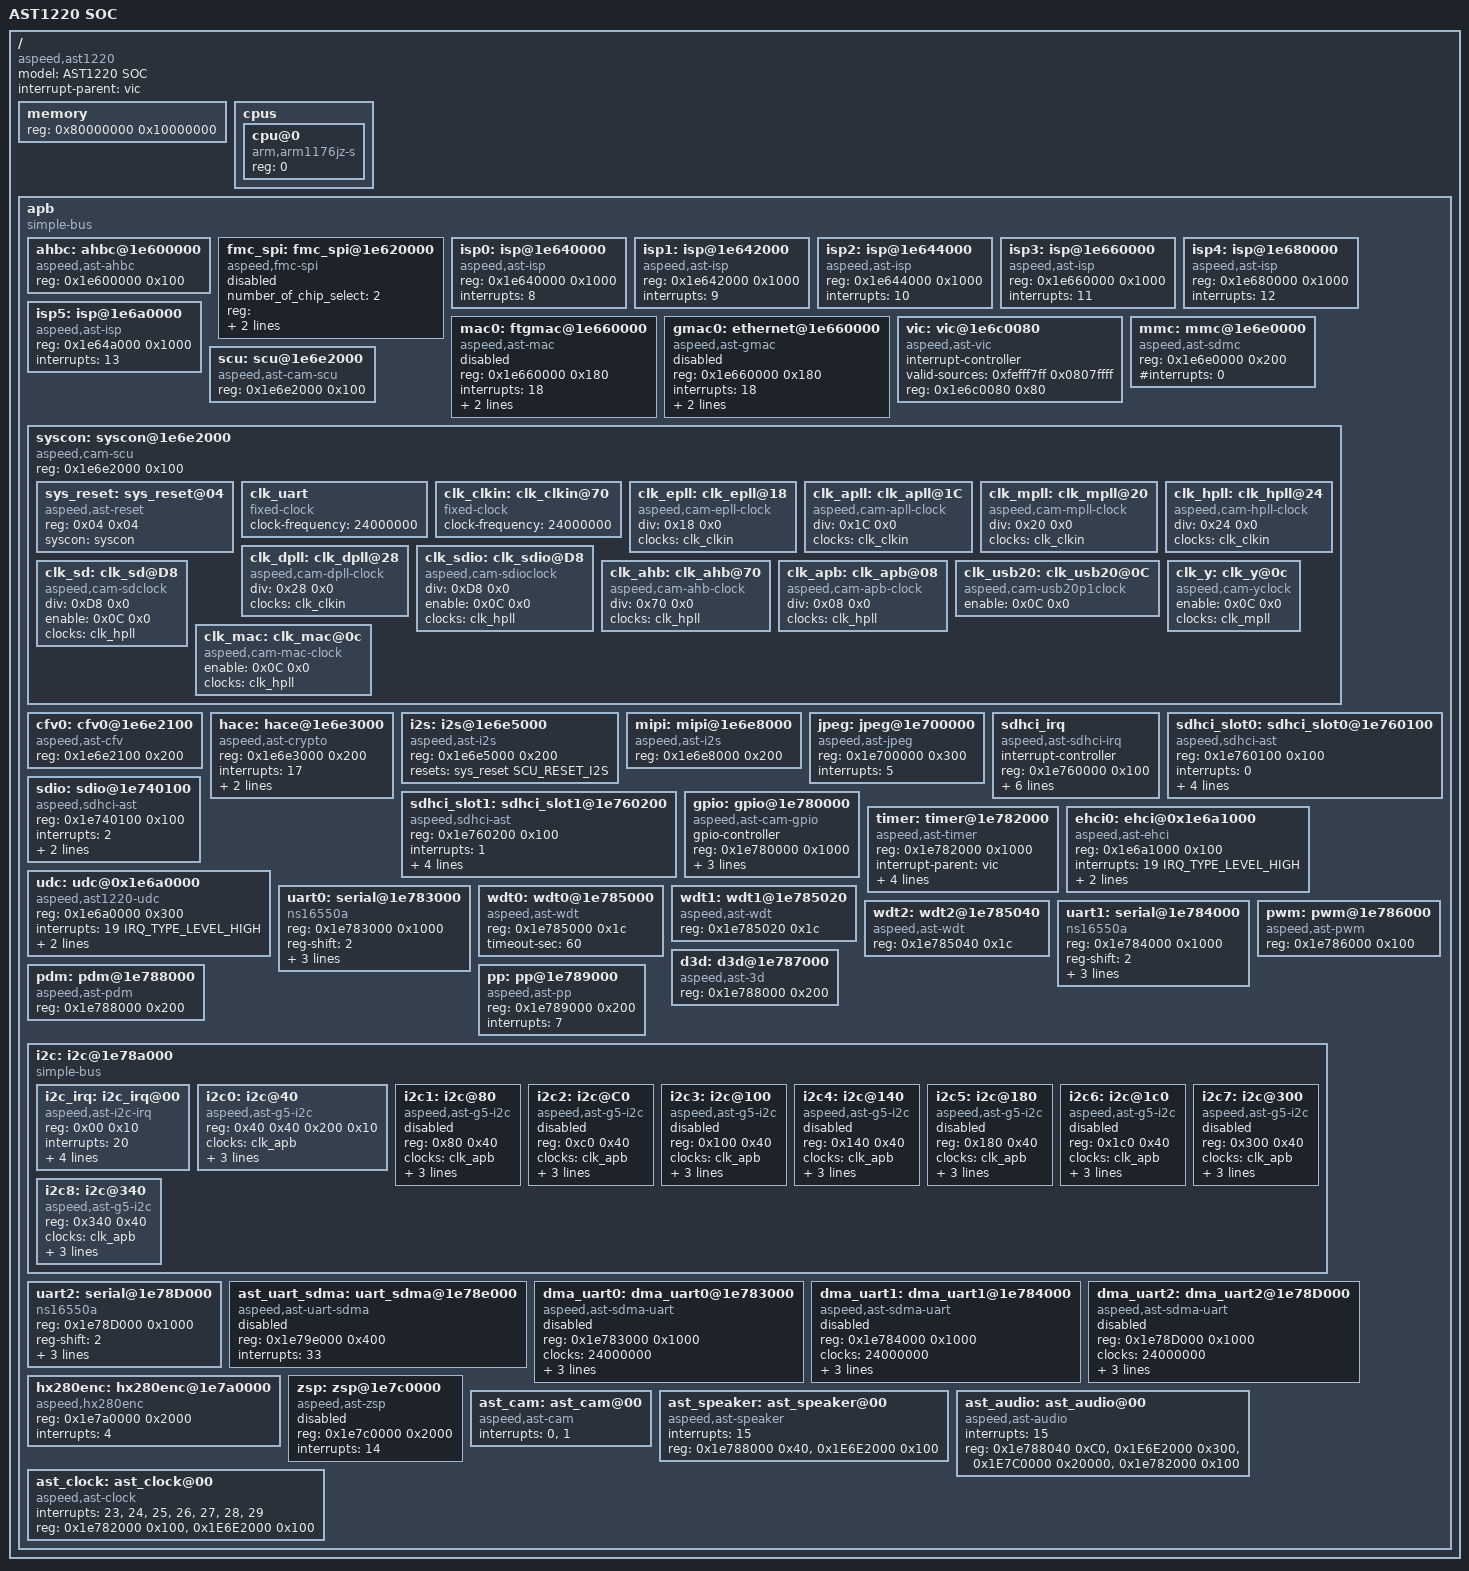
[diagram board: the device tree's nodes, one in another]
#include "skeleton.dtsi"
#include <dt-bindings/interrupt-controller/irq.h>
#include <dt-bindings/reset/ast-cam-reset.h>
#include <dt-bindings/gpio/gpio.h>

/ {
	model = "AST1220 SOC";
	compatible = "aspeed,ast1220";
	#address-cells = <1>;
	#size-cells = <1>;
	interrupt-parent = <&vic>;

	memory {
		reg = <0x80000000 0x10000000>;
	};

	cpus {
		#address-cells = <1>;
		#size-cells = <0>;

		cpu@0 {
			compatible = "arm,arm1176jz-s";
			device_type = "cpu";
			reg = <0>;
		};
	};

	apb {
		compatible = "simple-bus";
		#address-cells = <1>;
		#size-cells = <1>;
		ranges;

		ahbc: ahbc@1e600000 {
			compatible = "aspeed,ast-ahbc";
			reg = <0x1e600000 0x100>;
		};

		fmc_spi: fmc_spi@1e620000 {
			status = "disable";
			compatible = "aspeed,fmc-spi";
			number_of_chip_select = /bits/ 8 <2>;
			/* reg : cs0 : cs1 : cs2 : cs3 : cs4 : cs5 */
			reg = <0x1e620000 0x100 0x20000000 0x20 0x28000000 0x20>;
			#address-cells = <1>;
			#size-cells = <0>;
			clocks = <&clk_ahb>;
		};

		isp0: isp@1e640000 {
			compatible = "aspeed,ast-isp";
			reg = <0x1e640000 0x1000>;
			interrupts = <8>;
		};

		isp1: isp@1e642000 {
			compatible = "aspeed,ast-isp";
			reg = <0x1e642000 0x1000>;
			interrupts = <9>;
		};
		isp2: isp@1e644000 {
			compatible = "aspeed,ast-isp";
			reg = <0x1e644000 0x1000>;
			interrupts = <10>;
		};
		isp3: isp@1e660000 {
			compatible = "aspeed,ast-isp";
			reg = <0x1e660000 0x1000>;
			interrupts = <11>;
		};
		isp4: isp@1e680000 {
			compatible = "aspeed,ast-isp";
			reg = <0x1e680000 0x1000>;
			interrupts = <12>;
		};
		isp5: isp@1e6a0000 {
			compatible = "aspeed,ast-isp";
			reg = <0x1e64a000 0x1000>;
			interrupts = <13>;
		};
		mac0: ftgmac@1e660000 {
			compatible = "aspeed,ast-mac";
			reg = <0x1e660000 0x180>;
			interrupts = <18>;
			resets = <&sys_reset SCU_RESET_MAC>;
			reset-names = "mac";
			clocks = <&clk_mac>;
			status = "disabled";
		};

		gmac0: ethernet@1e660000 {
			compatible = "aspeed,ast-gmac";
			reg = <0x1e660000 0x180>;
			interrupts = <18>;
			resets = <&sys_reset SCU_RESET_MAC>;
			reset-names = "mac";
			clocks = <&clk_mac>;
			status = "disabled";
		};

		vic: vic@1e6c0080 {
			compatible = "aspeed,ast-vic";
			interrupt-controller;
			#interrupt-cells = <1>;
			valid-sources = <0xfefff7ff 0x0807ffff>;
			reg = <0x1e6c0080 0x80>;
		};

		mmc: mmc@1e6e0000 {
			compatible = "aspeed,ast-sdmc";
			reg = <0x1e6e0000 0x200>;
			#interrupts = <0>;
		}; 

		scu: scu@1e6e2000 {
			compatible = "aspeed,ast-cam-scu";
			reg = <0x1e6e2000 0x100>;
		};

		syscon: syscon@1e6e2000 {
			#address-cells = <1>;
			#size-cells = <1>;
			compatible = "aspeed,cam-scu", "syscon", "simple-mfd";
			reg = <0x1e6e2000 0x100>;
			ranges;
			sys_reset: sys_reset@04 {
				#reset-cells = <1>;
				compatible = "aspeed,ast-reset";
				reg = <0x04 0x04>;
				syscon = <&syscon>;
			};
			clk_uart: clk_uart {
				#clock-cells = <0>;
				compatible = "fixed-clock";
				clock-frequency = <24000000>;
			};
			clk_clkin: clk_clkin@70 {
				#clock-cells = <0>;
				compatible = "fixed-clock";
				clock-frequency = <24000000>;
			};
			clk_epll: clk_epll@18 {
				#clock-cells = <0>;
				compatible = "aspeed,cam-epll-clock";
				div = <0x18 0x0>;
				clocks = <&clk_clkin>;
			};
			clk_apll: clk_apll@1C {
				#clock-cells = <0>;
				compatible = "aspeed,cam-apll-clock";
				div = <0x1C 0x0>;
				clocks = <&clk_clkin>;
			};
			clk_mpll: clk_mpll@20 {
				#clock-cells = <0>;
				compatible = "aspeed,cam-mpll-clock";
				div = <0x20 0x0>;
				clocks = <&clk_clkin>;
			};
			clk_hpll: clk_hpll@24 {
				#clock-cells = <0>;
				compatible = "aspeed,cam-hpll-clock";
				div = <0x24 0x0>;
				clocks = <&clk_clkin>;
			};
			clk_dpll: clk_dpll@28 {
				#clock-cells = <0>;
				compatible = "aspeed,cam-dpll-clock";
				div = <0x28 0x0>;
				clocks = <&clk_clkin>;
			};
			clk_sdio:clk_sdio@D8 {
				#clock-cells = <0>;
				compatible = "aspeed,cam-sdioclock";
				div = <0xD8 0x0>;
				enable = <0x0C 0x0>;
				clocks = <&clk_hpll>;
			};
			clk_sd: clk_sd@D8 {
				#clock-cells = <0>;
				compatible = "aspeed,cam-sdclock";
				div = <0xD8 0x0>;
				enable = <0x0C 0x0>;
				clocks = <&clk_hpll>;
			};
			clk_ahb: clk_ahb@70 {
				#clock-cells = <0>;
				compatible = "aspeed,cam-ahb-clock";
				div = <0x70 0x0>;
				clocks = <&clk_hpll>;
			};
			clk_apb: clk_apb@08 {
				#clock-cells = <0>;
				compatible = "aspeed,cam-apb-clock";
				div = <0x08 0x0>;
				clocks = <&clk_hpll>;
			};
			clk_usb20: clk_usb20@0C {
				#clock-cells = <0>;
				compatible = "aspeed,cam-usb20p1clock";
				enable = <0x0C 0x0>;
			};
			clk_y: clk_y@0c {
				#clock-cells = <0>;
				compatible = "aspeed,cam-yclock";
				enable = <0x0C 0x0>;
				clocks = <&clk_mpll>;
			};
			clk_mac: clk_mac@0c {
				#clock-cells = <0>;
				compatible = "aspeed,cam-mac-clock";
				enable = <0x0C 0x0>;
				clocks = <&clk_hpll>;
			};
		};

		cfv0: cfv0@1e6e2100 {
			compatible = "aspeed,ast-cfv";
			reg = <0x1e6e2100 0x200>;
		};

		hace: hace@1e6e3000 {
			compatible = "aspeed,ast-crypto";
			reg = <0x1e6e3000 0x200>;
			interrupts = <17>;
			clocks = <&clk_y>;
			resets = <&sys_reset SCU_RESET_HACE>;
			reset-names = "crypto";
		};

		i2s: i2s@1e6e5000 {
			compatible = "aspeed,ast-i2s";
			reg = <0x1e6e5000 0x200>;
			resets = <&sys_reset SCU_RESET_I2S>;
		};

		mipi: mipi@1e6e8000 {
			compatible = "aspeed,ast-i2s";
			reg = <0x1e6e8000 0x200>;
		};

		jpeg: jpeg@1e700000 {
			compatible = "aspeed,ast-jpeg";
			reg = <0x1e700000 0x300>;
			interrupts = <5>;
		};

		sdhci_irq: sdhci_irq {
			compatible = "aspeed,ast-sdhci-irq";
			interrupt-controller;
                        #interrupt-cells = <1>;
			reg = <0x1e760000 0x100>;
			interrupts = <3>;
			slot_num = <2>;
			resets = <&sys_reset SCU_RESET_SDHCI>;
			reset-names = "sdhci";
			slot0-clk-delay = <0x8>;
			slot1-clk-delay = <0x8>;
			clocks = <&clk_sd>;
		};

		sdhci_slot0: sdhci_slot0@1e760100 {
			compatible = "aspeed,sdhci-ast";
			reg = <0x1e760100 0x100>;
			interrupts = <0>;
			interrupt-parent = <&sdhci_irq>;
			slot = <0>;
			sdhci,auto-cmd12;
			clocks = <&clk_sd>;
		};

		sdhci_slot1: sdhci_slot1@1e760200 {
			compatible = "aspeed,sdhci-ast";
			reg = <0x1e760200 0x100>;
			interrupts = <1>;
			interrupt-parent = <&sdhci_irq>;
			slot = <1>;
			sdhci,auto-cmd12;
			clocks = <&clk_sd>;
		};

		sdio: sdio@1e740100 {
			compatible = "aspeed,sdhci-ast";
			reg = <0x1e740100 0x100>;
			interrupts = <2>;
			resets = <&sys_reset SCU_RESET_SDIO>;
			reset-names = "sdhci";
			clocks = <&clk_sdio>;
		};

		gpio: gpio@1e780000 {
			#gpio-cells = <2>;
			gpio-controller;
			compatible = "aspeed,ast-cam-gpio";
			reg = <0x1e780000 0x1000>;
			interrupts = <21>;
			interrupt-controller;
			clocks = <&clk_apb>;
		};

		timer:timer@1e782000 {
			compatible = "aspeed,ast-timer";
			reg = <0x1e782000 0x1000>;
			interrupt-parent = <&vic>;
			interrupts = <22 IRQ_TYPE_EDGE_FALLING>, /* Timer 1 */
			         <23 IRQ_TYPE_EDGE_FALLING>, /* Timer 2 */
			         <24 IRQ_TYPE_EDGE_FALLING>; /* Timer 3 */
			clocks = <&clk_apb>;
			clock-names = "PCLK";
		};

        ehci0: ehci@0x1e6a1000 {
                compatible = "aspeed,ast-ehci", "generic-ehci";
                reg = <0x1e6a1000 0x100>;
                interrupts = <19 IRQ_TYPE_LEVEL_HIGH>;
                clocks = <&clk_usb20>;
                resets = <&sys_reset SCU_RESET_USB20>;
                reset-names = "ehci";
        };

        udc: udc@0x1e6a0000 {
                compatible = "aspeed,ast1220-udc";
                reg = <0x1e6a0000 0x300>;
                interrupts = <19 IRQ_TYPE_LEVEL_HIGH>;
                clocks = <&clk_usb20>;
                resets = <&sys_reset SCU_RESET_USB20>;
                reset-names = "udc";
        };

		uart0: serial@1e783000 {
			compatible = "ns16550a";
			reg = <0x1e783000 0x1000>;
			reg-shift = <2>;
			interrupts = <30 IRQ_TYPE_LEVEL_HIGH>;
			clocks = <&clk_uart>;
			no-loopback-test;
		};

		/* use for sys crash */
		wdt0: wdt0@1e785000 {
			compatible = "aspeed,ast-wdt";
			reg = <0x1e785000 0x1c>;
			timeout-sec = <60>;
		};
		/* use for spi 3/4 bytes reboot */
		wdt1: wdt1@1e785020 {
			compatible = "aspeed,ast-wdt";
			reg = <0x1e785020 0x1c>;
		};
		/* use for system reboot */		
		wdt2: wdt2@1e785040 {
			compatible = "aspeed,ast-wdt";
			reg = <0x1e785040 0x1c>;
		};

		uart1: serial@1e784000 {
			compatible = "ns16550a";
			reg = <0x1e784000 0x1000>;
			reg-shift = <2>;
			interrupts = <31 IRQ_TYPE_LEVEL_HIGH>;
			clocks = <&clk_uart>;
			no-loopback-test;
		};

		pwm: pwm@1e786000 {
			compatible = "aspeed,ast-pwm";
			reg = <0x1e786000 0x100>;
		};

		d3d: d3d@1e787000 {
			compatible = "aspeed,ast-3d";
			reg = <0x1e788000 0x200>;
		};

		pdm: pdm@1e788000 {
			compatible = "aspeed,ast-pdm";
			reg = <0x1e788000 0x200>;
		};

		pp: pp@1e789000 {
			compatible = "aspeed,ast-pp";
			reg = <0x1e789000 0x200>;
			interrupts = <7>;
		};

		i2c: i2c@1e78a000 {
			compatible = "simple-bus";
			#address-cells = <1>;
			#size-cells = <1>;
			ranges = <0 0x1e78a000 0x1000>;
		};

		uart2: serial@1e78D000 {
			compatible = "ns16550a";
			reg = <0x1e78D000 0x1000>;
			reg-shift = <2>;
			interrupts = <32 IRQ_TYPE_LEVEL_HIGH>;
			clocks = <&clk_uart>;
			no-loopback-test;
		};

		ast_uart_sdma: uart_sdma@1e78e000 {
			compatible = "aspeed,ast-uart-sdma";
			reg = <0x1e79e000 0x400>;
			interrupts = <33>;
			status = "disabled";
		};
		
		dma_uart0: dma_uart0@1e783000{
			compatible = "aspeed,ast-sdma-uart";
			reg = <0x1e783000 0x1000>;
			clocks = <24000000>;
			reg-shift = <2>;
			dma-channel = <2>;
			no-loopback-test;
			status = "disabled";
		};
		dma_uart1: dma_uart1@1e784000{
			compatible = "aspeed,ast-sdma-uart";
			reg = <0x1e784000 0x1000>;
			clocks = <24000000>;
			reg-shift = <2>;
			dma-channel = <3>;
			no-loopback-test;
			status = "disabled";
		};
		dma_uart2: dma_uart2@1e78D000{
			compatible = "aspeed,ast-sdma-uart";
			reg = <0x1e78D000 0x1000>;
			clocks = <24000000>;
			reg-shift = <2>;
			dma-channel = <4>;
			no-loopback-test;
			status = "disabled";
		};

		hx280enc: hx280enc@1e7a0000 {
			compatible = "aspeed,hx280enc";
			reg = <0x1e7a0000 0x2000>;
			interrupts = <4>;
		};

		zsp: zsp@1e7c0000 {
			compatible = "aspeed,ast-zsp";
			reg = <0x1e7c0000 0x2000>;
			interrupts = <14>;
			status = "disabled";
		};

		ast_cam: ast_cam@00 {
			compatible = "aspeed,ast-cam";
			interrupts = <0>, <1>;
		};
		ast_speaker: ast_speaker@00{
            compatible = "aspeed,ast-speaker";
            interrupts = <15>;
            reg = <0x1e788000 0x40> , <0x1E6E2000 0x100> ;
		};

		ast_audio: ast_audio@00{
            compatible = "aspeed,ast-audio";
            interrupts = <15>;
            reg = <0x1e788040 0xC0>,  <0x1E6E2000 0x300>, <0x1E7C0000 0x20000>,<0x1e782000 0x100>;
		};
		ast_clock: ast_clock@00{
            compatible = "aspeed,ast-clock";
            interrupts = <23>,<24>,<25>,<26>,<27>,<28>,<29>;
            reg = <0x1e782000 0x100> , <0x1E6E2000 0x100> ;
		};
	};

};

&i2c {
	i2c_irq: i2c_irq@00 {
		#interrupt-cells = <1>;
		compatible = "aspeed,ast-i2c-irq";
		reg = <0x00 0x10>;
		interrupts = <20>;
		interrupt-controller;
		bus_num = <9>;
		cmd-source = <0x5554>; /* I2C1 & I2C9 by ARM: 0, I2C2 ~ I2C8 by Coprocessor1: 1 */
		resets = <&sys_reset SCU_RESET_I2C>;
		reset-names = "i2c";		
	};

	i2c0: i2c@40 {
		reg = <0x40 0x40 0x200 0x10>;
		compatible = "aspeed,ast-g5-i2c", "aspeed,ast-dma-i2c";
		clocks = <&clk_apb>;
		bus-frequency = <100000>;
		interrupts = <0>;
		interrupt-parent = <&i2c_irq>;
	};

	i2c1: i2c@80 {
		reg = <0x80 0x40>;
		compatible = "aspeed,ast-g5-i2c";
		clocks = <&clk_apb>;
		bus-frequency = <100000>;
		interrupts = <1>;
		interrupt-parent = <&i2c_irq>;
		status = "disable";
	};
	i2c2: i2c@C0 {
		reg = <0xc0 0x40>;
		compatible = "aspeed,ast-g5-i2c";
		clocks = <&clk_apb>;
		bus-frequency = <100000>;
		interrupts = <2>;
		interrupt-parent = <&i2c_irq>;
		status = "disable";
	};
	i2c3: i2c@100 {
		reg = <0x100 0x40>;
		compatible = "aspeed,ast-g5-i2c";
		clocks = <&clk_apb>;
		bus-frequency = <100000>;
		interrupts = <3>;
		interrupt-parent = <&i2c_irq>;
		status = "disable";
	};
	i2c4: i2c@140 {
		reg = <0x140 0x40>;
		compatible = "aspeed,ast-g5-i2c";
		clocks = <&clk_apb>;
		bus-frequency = <100000>;
		interrupts = <4>;
		interrupt-parent = <&i2c_irq>;
		status = "disable";
	};
	i2c5: i2c@180 {
		reg = <0x180 0x40>;
		compatible = "aspeed,ast-g5-i2c";
		clocks = <&clk_apb>;
		bus-frequency = <100000>;
		interrupts = <5>;
		interrupt-parent = <&i2c_irq>;
		status = "disable";
	};
	i2c6: i2c@1c0 {
		reg = <0x1c0 0x40>;
		compatible = "aspeed,ast-g5-i2c";
		clocks = <&clk_apb>;
		bus-frequency = <100000>;
		interrupts = <6>;
		interrupt-parent = <&i2c_irq>;
		status = "disable";
	};
	i2c7: i2c@300 {
		reg = <0x300 0x40>;
		compatible = "aspeed,ast-g5-i2c";
		clocks = <&clk_apb>;
		bus-frequency = <100000>;
		interrupts = <7>;
		interrupt-parent = <&i2c_irq>;
		status = "disable";
	};
	i2c8: i2c@340 {
		reg = <0x340 0x40>;
		compatible = "aspeed,ast-g5-i2c", "aspeed,ast-dma-i2c";
		clocks = <&clk_apb>;
		bus-frequency = <100000>;
		interrupts = <8>;
		interrupt-parent = <&i2c_irq>;
	};
};
